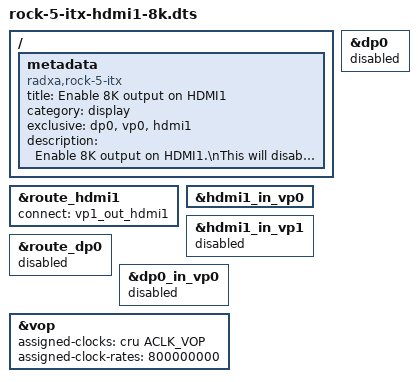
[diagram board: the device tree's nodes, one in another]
/dts-v1/;
/plugin/;
#include <dt-bindings/clock/rk3588-cru.h>

/ {
	metadata {
		title = "Enable 8K output on HDMI1";
		compatible = "radxa,rock-5-itx";
		category = "display";
		exclusive = "dp0", "vp0", "hdmi1";
		description = "Enable 8K output on HDMI1.\nThis will disable DP0.";
	};

	fragment@0 {
		target = <&route_hdmi1>;

		__overlay__ {
			connect = <&vp1_out_hdmi1>;
			status = "okay";
		};
	};

	fragment@1 {
		target = <&hdmi1_in_vp0>;

		__overlay__ {
			status = "okay";
		};
	};

	fragment@2 {
		target = <&hdmi1_in_vp1>;

		__overlay__ {
			status = "disabled";
		};
	};

	fragment@3 {
		target = <&route_dp0>;

		__overlay__ {
			status = "disabled";
		};
	};

	fragment@4 {
		target = <&dp0>;

		__overlay__ {
			status = "disabled";
		};
	};


	fragment@5 {
		target = <&dp0_in_vp0>;

		__overlay__ {
			status = "disabled";
		};
	};

	fragment@6 {
		target = <&vop>;

		__overlay__ {
			assigned-clocks = <&cru ACLK_VOP>;
			assigned-clock-rates = <800000000>;
		};
	};
};
